# NUC505_v1 register map
File version: 1.0
Registers are 32-bit, read-write, reset 0x0 unless marked. A register's access mark holds for its fields unless they carry their own. Offsets are from the block's base; [hi:lo] are bit positions; 'fields as' and 'values as' point back to an identical list.

## USBD — USBD Register Map
Base 0x40019000
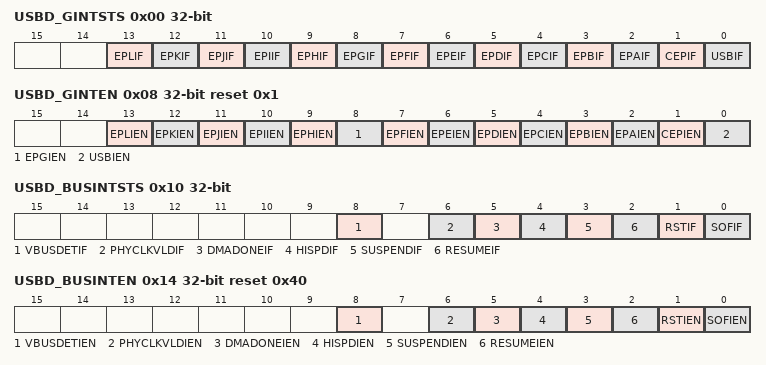
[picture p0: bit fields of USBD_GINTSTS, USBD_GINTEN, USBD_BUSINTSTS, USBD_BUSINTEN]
0x00 USBD_GINTSTS ro — Global Interrupt Status Register
  [all] fields
    0=No interrupt event occurred; 1=The related interrupt event is occurred
  [13] EPLIF — Endpoints L Interrupt. When set, the corresponding Endpoint L's interrupt status register should be read to determine the cause of the interrupt.
  [12] EPKIF — Endpoints K Interrupt. When set, the corresponding Endpoint K's interrupt status register should be read to determine the cause of the interrupt.
  [11] EPJIF — Endpoints J Interrupt. When set, the corresponding Endpoint J's interrupt status register should be read to determine the cause of the interrupt.
  [10] EPIIF — Endpoints I Interrupt. When set, the corresponding Endpoint I's interrupt status register should be read to determine the cause of the interrupt.
  [9] EPHIF — Endpoints H Interrupt. When set, the corresponding Endpoint H's interrupt status register should be read to determine the cause of the interrupt.
  [8] EPGIF — Endpoints G Interrupt. When set, the corresponding Endpoint G's interrupt status register should be read to determine the cause of the interrupt.
  [7] EPFIF — Endpoints F Interrupt. When set, the corresponding Endpoint F's interrupt status register should be read to determine the cause of the interrupt.
  [6] EPEIF — Endpoints E Interrupt. When set, the corresponding Endpoint E's interrupt status register should be read to determine the cause of the interrupt.
  [5] EPDIF — Endpoints D Interrupt. When set, the corresponding Endpoint D's interrupt status register should be read to determine the cause of the interrupt.
  [4] EPCIF — Endpoints C Interrupt. When set, the corresponding Endpoint C's interrupt status register should be read to determine the cause of the interrupt.
  [3] EPBIF — Endpoints B Interrupt. When set, the corresponding Endpoint B's interrupt status register should be read to determine the cause of the interrupt.
  [2] EPAIF — Endpoints a Interrupt. When set, the corresponding Endpoint A's interrupt status register should be read to determine the cause of the interrupt.
  [1] CEPIF — Control Endpoint Interrupt. This bit conveys the interrupt status for control endpoint. When set, Control-ep's interrupt status register should be read to determine the cause of the interrupt.
  [0] USBIF — USB Interrupt. This bit conveys the interrupt status for USB specific events endpoint. When set, USB interrupt status register should be read to determine the cause of the interrupt.
0x08 USBD_GINTEN reset 0x1 — Global Interrupt Enable Register
  [all] fields
    0=The related interrupt Disabled; 1=The related interrupt Enabled
  [13] EPLIEN — Interrupt Enable Control for Endpoint L. When set, this bit enables a local interrupt to be generated when an interrupt is pending for the endpoint L
  [12] EPKIEN — Interrupt Enable Control for Endpoint K. When set, this bit enables a local interrupt to be generated when an interrupt is pending for the endpoint K
  [11] EPJIEN — Interrupt Enable Control for Endpoint J. When set, this bit enables a local interrupt to be generated when an interrupt is pending for the endpoint J
  [10] EPIIEN — Interrupt Enable Control for Endpoint I. When set, this bit enables a local interrupt to be generated when an interrupt is pending for the endpoint I
  [9] EPHIEN — Interrupt Enable Control for Endpoint H. When set, this bit enables a local interrupt to be generated when an interrupt is pending for the endpoint H
  [8] EPGIEN — Interrupt Enable Control for Endpoint G. When set, this bit enables a local interrupt to be generated when an interrupt is pending for the endpoint G
  [7] EPFIEN — Interrupt Enable Control for Endpoint F. When set, this bit enables a local interrupt to be generated when an interrupt is pending for the endpoint F
  [6] EPEIEN — Interrupt Enable Control for Endpoint E. When set, this bit enables a local interrupt to be generated when an interrupt is pending for the endpoint E
  [5] EPDIEN — Interrupt Enable Control for Endpoint D. When set, this bit enables a local interrupt to be generated when an interrupt is pending for the endpoint D
  [4] EPCIEN — Interrupt Enable Control for Endpoint C. When set, this bit enables a local interrupt to be generated when an interrupt is pending for the endpoint C
  [3] EPBIEN — Interrupt Enable Control for Endpoint B. When set, this bit enables a local interrupt to be generated when an interrupt is pending for the endpoint B
  [2] EPAIEN — Interrupt Enable Control for Endpoint a. When set, this bit enables a local interrupt to be generated when an interrupt is pending for the endpoint A.
  [1] CEPIEN — Control Endpoint Interrupt Enable Bit. When set, this bit enables a local interrupt to be generated when an interrupt is pending for the control endpoint.
  [0] USBIEN — USB Interrupt Enable Bit. When set, this bit enables a local interrupt to be generated when a USB event occurs on the bus.
0x10 USBD_BUSINTSTS — USB Bus Interrupt Status Register
  [8] VBUSDETIF — VBUS Detection Interrupt Status. Write 1 to clear this bit to 0.
    0=No VBUS is plug-in; 1=VBUS is plug-in
  [6] PHYCLKVLDIF — Usable Clock Interrupt. Write 1 to clear this bit to 0.
    0=Usable clock is not available; 1=Usable clock is available from the transceiver
  [5] DMADONEIF — DMA Completion Interrupt. Write 1 to clear this bit to 0.
    0=No DMA transfer over; 1=DMA transfer is over
  [4] HISPDIF — High-speed Settle. Write 1 to clear this bit to 0.
    0=No valid high-speed reset protocol is detected; 1=Valid high-speed reset protocol is over and the device has settled in high-speed
  [3] SUSPENDIF — Suspend Request. This bit is set as default and it has to be cleared by writing '1' before the USB reset. This bit is also set when a USB Suspend request is detected from the host. Write 1 to clear this bit to 0.
    0=No USB Suspend request is detected from the host; 1=USB Suspend request is detected from the host
  [2] RESUMEIF — Resume. When set, this bit indicates that a device resume has occurred. Write 1 to clear this bit to 0.
    0=No device resume has occurred; 1=Device resume has occurred
  [1] RSTIF — Reset Status. When set, this bit indicates that either the USB root port reset is end. Write 1 to clear this bit to 0.
    0=No USB root port reset is end; 1=USB root port reset is end
  [0] SOFIF — SOF Receive Control. This bit indicates when a start-of-frame packet has been received. Write 1 to clear this bit to 0.
    0=No start-of-frame packet has been received; 1=Start-of-frame packet has been received
0x14 USBD_BUSINTEN reset 0x40 — USB Bus Interrupt Enable Register
  [8] VBUSDETIEN — VBUS Detection Interrupt Enable Control. This bit enables the VBUS floating detection interrupt.
    0=VBUS floating detection interrupt Disabled; 1=VBUS floating detection interrupt Enabled
  [6] PHYCLKVLDIEN — Usable Clock Interrupt. This bit enables the usable clock interrupt.
    0=Usable clock interrupt Disabled; 1=Usable clock interrupt Enabled
  [5] DMADONEIEN — DMA Completion Interrupt. This bit enables the DMA completion interrupt
    0=DMA completion interrupt Disabled; 1=DMA completion interrupt Enabled
  [4] HISPDIEN — High-speed Settle. This bit enables the high-speed settle interrupt.
    0=High-speed settle interrupt Disabled; 1=High-speed settle interrupt Enabled
  [3] SUSPENDIEN — Suspend Request. This bit enables the Suspend interrupt.
    0=Suspend interrupt Disabled; 1=Suspend interrupt Enabled
  [2] RESUMEIEN — Resume. This bit enables the Resume interrupt.
    0=Resume interrupt Disabled; 1=Resume interrupt Enabled
  [1] RSTIEN — Reset Status. This bit enables the USB-Reset interrupt.
    0=USB-Reset interrupt Disabled; 1=USB-Reset interrupt Enabled
  [0] SOFIEN — SOF Interrupt. This bit enables the SOF interrupt.
    0=SOF interrupt Disabled; 1=SOF interrupt Enabled
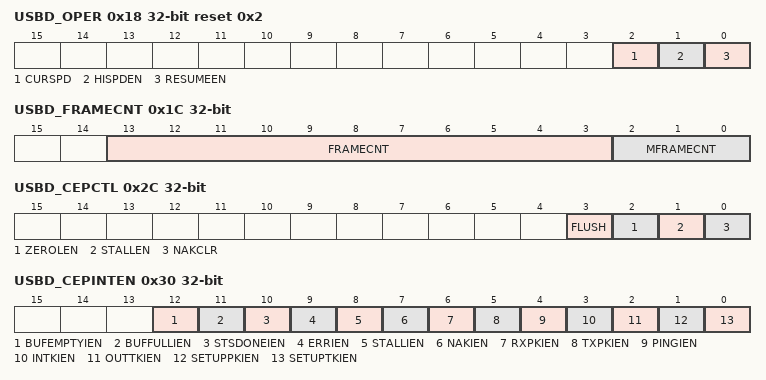
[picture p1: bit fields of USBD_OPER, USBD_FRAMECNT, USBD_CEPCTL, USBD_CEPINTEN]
0x18 USBD_OPER reset 0x2 — USB Operational Register
  [2] CURSPD — Current USB Speed
    0=The device has settled in Full Speed; 1=The USB device controller has settled in High Speed
  [1] HISPDEN — USB High-speed
    0=The USB device controller suppresses the chirp-sequence during reset protocol, thereby allowing the USB device controller to settle in full-speed, even though it is connected to a USB2.0 Host; 1=The USB device controller initiates a chirp-sequence during reset protocol
  [0] RESUMEEN — Generate Resume
    0=No resume sequence to be initiated to the host; 1=A resume sequence to be initiated to the host if device remote wake-up is enabled. Note: This bit is self-cleared
0x1C USBD_FRAMECNT ro — USB Frame Count Register
  [13:3] FRAMECNT — Frame Counter. This field contains the frame count from the most recent start-of-frame packet.
  [2:0] MFRAMECNT — Micro-frame Counter. This field contains the micro-frame number for the frame number in the frame counter field.
0x20 USBD_FADDR — USB Function Address Register
  [6:0] FADDR — USB Function Address. This field contains the current USB address of the device. This field is cleared when a root port reset is detected.
0x24 USBD_TEST — USB Test Mode Register
  [2:0] TESTMODE — Test Mode Selection. Note: This field is cleared when root port reset is detected.
    0=Normal Operation; 1=Test_J; 2=Test_K; 3=Test_SE0_NAK; 4=Test_Packet; 5=Test_Force_Enable
0x28 USBD_CEPDAT — Control-endpoint Data Buffer
  [31:0] DAT — Control-endpoint Data Buffer. Control endpoint data buffer for the buffer transaction (read or write). Only word or byte access is supported.
0x2C USBD_CEPCTL — Control-endpoint Control Register
  [3] FLUSH — CEP-fLUSH Bit
    0=No packet buffer and its corresponding USBD_CEPDATCNT register to be cleared; 1=The packet buffer and its corresponding USBD_CEPDATCNT register to be cleared. This bit is self-cleared
  [2] ZEROLEN — Zero Packet Length. This bit is valid for Auto Validation mode only.
    0=No zero length packet to the host during Data stage to an IN token; 1=USB device controller can send a zero length packet to the host during Data stage to an IN token. This bit gets cleared once the zero length data packet is sent. Thus, the local CPU does not need to write again to clear this bit
  [1] STALLEN — Stall Enable Control. When this stall bit is set, the control endpoint sends a stall handshake in response to any in or out token thereafter. This is typically used for response to invalid/unsupported requests. When this bit is being set the NAK clear bit has to be cleared at the same time since the NAK clear bit has highest priority than STALL. It is automatically cleared on receipt of a next setup-token. Thus, the local CPU does not need to write again to clear this bit. Note: This bit can be updated only when CPU writes data[1:0] 0x2 or 0x0.
    0=No sends a stall handshake in response to any in or out token thereafter; 1=The control endpoint sends a stall handshake in response to any in or out token thereafter
  [0] NAKCLR — No Acknowledge Control. This bit plays a crucial role in any control transfer. Note: This bit can be updated only when CPU writes data[1:0] is 0x2 or 0x0.
    0=The bit is being cleared by the local CPU by writing zero, the USB device controller will be responding with NAKs for the subsequent status phase. This mechanism holds the host from moving to the next request, until the local CPU is also ready to process the next request; 1=This bit is set to one by the USB device controller, whenever a setup token is received. The local CPU can take its own time to finish off any house-keeping work based on the request and then clear this bit
0x30 USBD_CEPINTEN — Control-endpoint Interrupt Enable Control Register
  [12] BUFEMPTYIEN — Buffer Empty Interrupt
    0=The buffer empty interrupt in Control Endpoint Disabled; 1=The buffer empty interrupt in Control Endpoint Enabled
  [11] BUFFULLIEN — Buffer Full Interrupt
    0=The buffer full interrupt in Control Endpoint Disabled; 1=The buffer full interrupt in Control Endpoint Enabled
  [10] STSDONEIEN — Status Completion Interrupt
    0=The Status Completion interrupt in Control Endpoint Disabled; 1=The Status Completion interrupt in Control Endpoint Enabled
  [9] ERRIEN — USB Error Interrupt
    0=The USB Error interrupt in Control Endpoint Disabled; 1=The USB Error interrupt in Control Endpoint Enabled
  [8] STALLIEN — STALL Sent Interrupt
    0=The STALL sent interrupt in Control Endpoint Disabled; 1=The STALL sent interrupt in Control Endpoint Enabled
  [7] NAKIEN — NAK Sent Interrupt
    0=The NAK sent interrupt in Control Endpoint Disabled; 1=The NAK sent interrupt in Control Endpoint Enabled
  [6] RXPKIEN — Data Packet Received Interrupt
    0=The data received interrupt in Control Endpoint Disabled; 1=The data received interrupt in Control Endpoint Enabled
  [5] TXPKIEN — Data Packet Transmitted Interrupt
    0=The data packet transmitted interrupt in Control Endpoint Disabled; 1=The data packet transmitted interrupt in Control Endpoint Enabled
  [4] PINGIEN — Ping Token Interrupt
    0=The ping token interrupt in Control Endpoint Disabled; 1=The ping token interrupt Control Endpoint Enabled
  [3] INTKIEN — in Token Interrupt
    0=The IN token interrupt in Control Endpoint Disabled; 1=The IN token interrupt in Control Endpoint Enabled
  [2] OUTTKIEN — Out Token Interrupt
    0=The OUT token interrupt in Control Endpoint Disabled; 1=The OUT token interrupt in Control Endpoint Enabled
  [1] SETUPPKIEN — Setup Packet Interrupt
    0=The SETUP packet interrupt in Control Endpoint Disabled; 1=The SETUP packet interrupt in Control Endpoint Enabled
  [0] SETUPTKIEN — Setup Token Interrupt Enable Bit
    0=The SETUP token interrupt in Control Endpoint Disabled; 1=The SETUP token interrupt in Control Endpoint Enabled
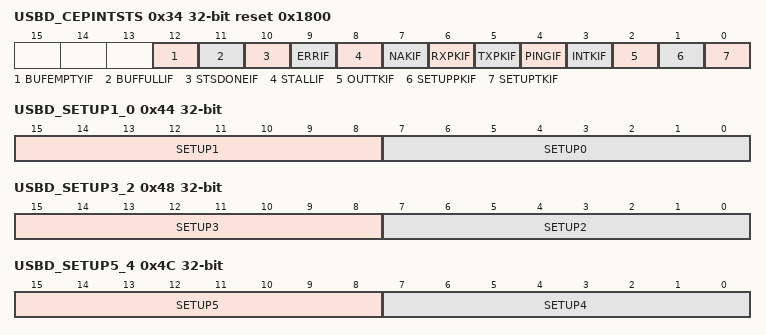
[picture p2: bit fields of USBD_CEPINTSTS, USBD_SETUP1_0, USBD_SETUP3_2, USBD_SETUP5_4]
0x34 USBD_CEPINTSTS reset 0x1800 — Control-endpoint Interrupt Status
  [12] BUFEMPTYIF — Buffer Empty Interrupt. Note: Write 1 to clear this bit to 0.
    0=The control-endpoint buffer is not empty; 1=The control-endpoint buffer is empty
  [11] BUFFULLIF — Buffer Full Interrupt. Note: Write 1 to clear this bit to 0.
    0=The control-endpoint buffer is not full; 1=The control-endpoint buffer is full
  [10] STSDONEIF — Status Completion Interrupt. Note: Write 1 to clear this bit to 0.
    0=No USB transaction has completed successfully; 1=The status stage of a USB transaction has completed successfully
  [9] ERRIF — USB Error Interrupt. Note: Write 1 to clear this bit to 0.
    0=No error had occurred during the transaction; 1=An error had occurred during the transaction
  [8] STALLIF — STALL Sent Interrupt. Note: Write 1 to clear this bit to 0.
    0=No stall-token is sent in response to an IN/OUT token; 1=A stall-token is sent in response to an IN/OUT token
  [7] NAKIF — NAK Sent Interrupt. Note: Write 1 to clear this bit to 0.
    0=No NAK-token is sent in response to an IN/OUT token; 1=A NAK-token is sent in response to an IN/OUT token
  [6] RXPKIF — Data Packet Received Interrupt. Note: Write 1 to clear this bit to 0.
    0=No data packet is successfully received from the host for an OUT-token and an ACK is sent to the host; 1=A data packet is successfully received from the host for an OUT-token and an ACK is sent to the host
  [5] TXPKIF — Data Packet Transmitted Interrupt. Note: Write 1 to clear this bit to 0.
    0=No data packet is successfully transmitted to the host in response to an IN-token and an ACK-token is received for the same; 1=A data packet is successfully transmitted to the host in response to an IN-token and an ACK-token is received for the same
  [4] PINGIF — Ping Token Interrupt. Note: Write 1 to clear this bit to 0.
    0=The control-endpoint does not receive a ping token from the host; 1=The control-endpoint receives a ping token from the host
  [3] INTKIF — in Token Interrupt. Write 1 to clear this bit to 0.
    0=The control-endpoint does not receive an IN token from the host; 1=The control-endpoint receives an IN token from the host
  [2] OUTTKIF — Out Token Interrupt. Note: Write 1 to clear this bit to 0.
    0=The control-endpoint does not receive an OUT token from the host; 1=The control-endpoint receives an OUT token from the host
  [1] SETUPPKIF — Setup Packet Interrupt. This bit must be cleared (by writing 1) before the next setup packet can be received. If the bit is not cleared, then the successive setup packets will be overwritten in the setup packet buffer. Note: Write 1 to clear this bit to 0.
    0=No setup packet has been received from the host; 1=A setup packet has been received from the host
  [0] SETUPTKIF — Setup Token Interrupt. Note: Write 1 to clear this bit to 0.
    0=No setup token is received; 1=A setup token is received. Writing 1 clears this status bit
0x38 USBD_CEPTXCNT — Control-endpoint In-transfer Data Count
  [7:0] TXCNT — In-transfer Data Count. There is no mode selection for the control endpoint (but it operates like manual mode).The local-CPU has to fill the control-endpoint buffer with the data to be sent for an in-token and to write the count of bytes in this register. When zero is written into this field, a zero length packet is sent to the host. When the count written in the register is more than the MPS, the data sent will be of only MPS.
0x3C USBD_CEPRXCNT ro — Control-endpoint Out-transfer Data Count
  [7:0] RXCNT — Out-transfer Data Count. The USB device controller maintains the count of the data received in case of an out transfer, during the control transfer.
0x40 USBD_CEPDATCNT ro — Control-endpoint Data Count
  [15:0] DATCNT — Control-endpoint Data Count. The USB device controller maintains the count of the data of control-endpoint.
0x44 USBD_SETUP1_0 ro — Setup1 Setup0 Bytes
  [15:8] SETUP1 — Setup Byte 1[15:8]. This register provides byte 1 of the last setup packet received. For a Standard Device Request, the following bRequest Code information is returned.
    0=Get Status; 1=Clear Feature; 3=Set Feature; 5=Set Address; 6=Get Descriptor; 7=Set Descriptor; 8=Get Configuration; 9=Set Configuration; 10=Get Interface; 11=Set Interface; 12=Synch Frame
  [7:0] SETUP0 — Setup Byte 0[7:0]. This register provides byte 0 of the last setup packet received. For a Standard Device Request, the following bmRequestType information is returned. Bit 7(Direction):
    0=Host to device. Standard. Device; 1=Device to host. Class. nterface; 10=Vendor. Endpoint; 11=Reserved. :Other
0x48 USBD_SETUP3_2 ro — Setup3 Setup2 Bytes
  [15:8] SETUP3 — Setup Byte 3 [15:8]. This register provides byte 3 of the last setup packet received. For a Standard Device Request, the most significant byte of the wValue field is returned.
  [7:0] SETUP2 — Setup Byte 2 [7:0]. This register provides byte 2 of the last setup packet received. For a Standard Device Request, the least significant byte of the wValue field is returned.
0x4C USBD_SETUP5_4 ro — Setup5 Setup4 Bytes
  [15:8] SETUP5 — Setup Byte 5[15:8]. This register provides byte 5 of the last setup packet received. For a Standard Device Request, the most significant byte of the wIndex field is returned.
  [7:0] SETUP4 — Setup Byte 4[7:0]. This register provides byte 4 of the last setup packet received. For a Standard Device Request, the least significant byte of the wIndex is returned.
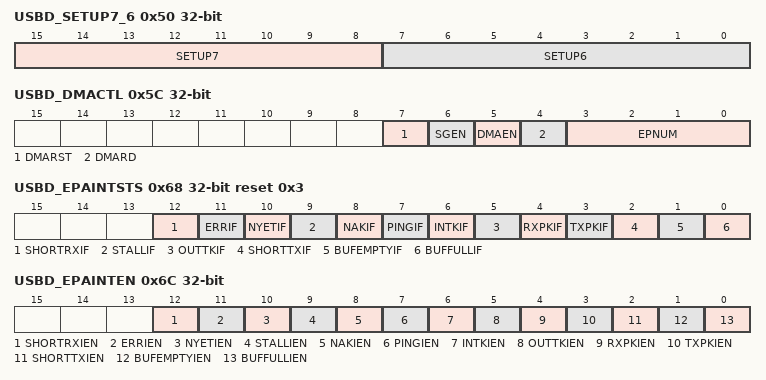
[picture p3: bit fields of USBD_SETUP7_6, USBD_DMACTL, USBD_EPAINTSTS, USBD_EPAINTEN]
0x50 USBD_SETUP7_6 ro — Setup7 Setup6 Bytes
  [15:8] SETUP7 — Setup Byte 7[15:8]. This register provides byte 7 of the last setup packet received. For a Standard Device Request, the most significant byte of the wLength field is returned.
  [7:0] SETUP6 — Setup Byte 6[7:0]. This register provides byte 6 of the last setup packet received. For a Standard Device Request, the least significant byte of the wLength field is returned.
0x54 USBD_CEPBUFSTART — Control Endpoint RAM Start Address Register
  [11:0] SADDR — Control-endpoint Start Address. This is the start-address of the RAM space allocated for the control-endpoint.
0x58 USBD_CEPBUFEND — Control Endpoint RAM End Address Register
  [11:0] EADDR — Control-endpoint End Address. This is the end-address of the RAM space allocated for the control-endpoint.
0x5C USBD_DMACTL — DMA Control Status Register
  [7] DMARST — Reset DMA State Machine
    0=No reset the DMA state machine; 1=Reset the DMA state machine
  [6] SGEN — Scatter Gather Function Enable Bit
    0=Scatter gather function Disabled; 1=Scatter gather function Enabled
  [5] DMAEN — DMA Enable Bit
    0=DMA function Disabled; 1=DMA function Enabled
  [4] DMARD — DMA Operation
    0=The operation is a DMA write (read from USB buffer). DMA will check endpoint data available count (USBD_EPxDATCNT) according to EPNM setting before to perform DMA write operation; 1=The operation is a DMA read (write to USB buffer)
  [3:0] EPNUM — DMA Endpoint Address Bits. Used to define the Endpoint Address
0x60 USBD_DMACNT — DMA Count Register
  [19:0] DMACNT — DMA Transfer Count. The transfer count of the DMA operation to be performed is written to this register.
0x64 USBD_EPADAT — Endpoint A Data Register
  [31:0] EPDAT — Endpoint A~L Data Register. Endpoint A~L data buffer for the buffer transaction (read or write). Only word or byte access are supported.
0x68 USBD_EPAINTSTS reset 0x3 — Endpoint A Interrupt Status Register
  [12] SHORTRXIF — Bulk Out Short Packet Received. Write 1 to clear this bit to 0.
    0=No bulk out short packet is received; 1=Received bulk out short packet (including zero length packet)
  [11] ERRIF — ERR Sent. Write 1 to clear this bit to 0.
    0=No any error in the transaction; 1=There occurs any error in the transaction
  [10] NYETIF — NYET Sent. Write 1 to clear this bit to 0.
    0=The space available in the RAM is sufficient to accommodate the next on coming data packet; 1=The space available in the RAM is not sufficient to accommodate the next on coming data packet
  [9] STALLIF — USB STALL Sent. Write 1 to clear this bit to 0.
    0=The last USB packet could be accepted or provided because the endpoint was stalled, and was acknowledged with a STALL; 1=The last USB packet could not be accepted or provided because the endpoint was stalled, and was acknowledged with a STALL
  [8] NAKIF — USB NAK Sent. Write 1 to clear this bit to 0.
    0=The last USB IN packet could be provided, and was acknowledged with an ACK; 1=The last USB IN packet could not be provided, and was acknowledged with a NAK
  [7] PINGIF — PING Token Interrupt. Write 1 to clear this bit to 0.
    0=A Data PING token has not been received from the host; 1=A Data PING token has been received from the host
  [6] INTKIF — Data IN Token Interrupt. Write 1 to clear this bit to 0.
    0=No Data IN token has been received from the host; 1=A Data IN token has been received from the host
  [5] OUTTKIF — Data OUT Token Interrupt. Note: Write 1 to clear this bit to 0.
    0=A Data OUT token has not been received from the host; 1=A Data OUT token has been received from the host. This bit also set by PING token (in high-speed only)
  [4] RXPKIF — Data Packet Received Interrupt. Note: Write 1 to clear this bit to 0.
    0=No data packet is received from the host by the endpoint; 1=A data packet is received from the host by the endpoint
  [3] TXPKIF — Data Packet Transmitted Interrupt. Note: Write 1 to clear this bit to 0.
    0=No data packet is transmitted from the endpoint to the host; 1=A data packet is transmitted from the endpoint to the host
  [2] SHORTTXIF — Short Packet Transferred Interrupt. Note: Write 1 to clear this bit to 0.
    0=The length of the last packet was not less than the Maximum Packet Size (EPMPS); 1=The length of the last packet was less than the Maximum Packet Size (EPMPS)
  [1] BUFEMPTYIF — Buffer Empty. For an IN endpoint, a buffer is available to the local side for writing up to FIFO full of bytes. Note: This bit is read-only.
    0=The endpoint buffer is not empty. The currently selected buffer does not have a count of 0; 1=The endpoint buffer is empty. The currently selected buffer has a count of 0, or no buffer is available on the local side (nothing to read)
  [0] BUFFULLIF — Buffer Full. For an IN endpoint, the currently selected buffer is full, or no buffer is available to the local side for writing (no space to write). For an OUT endpoint, there is a buffer available on the local side, and there are FIFO full of bytes available to be read (entire packet is available for reading). Note: This bit is read-only.
    0=The endpoint packet buffer is not full; 1=The endpoint packet buffer is full
0x6C USBD_EPAINTEN — Endpoint A Interrupt Enable Register
  [12] SHORTRXIEN — Bulk Out Short Packet Interrupt Enable Bit. When set, this bit enables a local interrupt to be set whenever bulk out short packet occurs on the bus for this endpoint.
    0=Bulk out interrupt Disabled; 1=Bulk out interrupt Enabled
  [11] ERRIEN — ERR Interrupt Enable Bit. When set, this bit enables a local interrupt to be set whenever ERR condition occurs on the bus for this endpoint.
    0=Error event interrupt Disabled; 1=Error event interrupt Enabled
  [10] NYETIEN — NYET Interrupt Enable Bit. When set, this bit enables a local interrupt to be set whenever NYET condition occurs on the bus for this endpoint.
    0=NYET condition interrupt Disabled; 1=NYET condition interrupt Enabled
  [9] STALLIEN — USB STALL Sent Interrupt Enable Bit. When set, this bit enables a local interrupt to be set when a stall token is sent to the host.
    0=STALL token interrupt Disabled; 1=STALL token interrupt Enabled
  [8] NAKIEN — USB NAK Sent Interrupt Enable Bit. When set, this bit enables a local interrupt to be set when a NAK token is sent to the host.
    0=NAK token interrupt Disabled; 1=NAK token interrupt Enabled
  [7] PINGIEN — PING Token Interrupt Enable Bit. When set, this bit enables a local interrupt to be set when a PING token has been received from the host.
    0=PING token interrupt Disabled; 1=PING token interrupt Enabled
  [6] INTKIEN — Data IN Token Interrupt Enable Bit. When set, this bit enables a local interrupt to be set when a Data IN token has been received from the host.
    0=Data IN token interrupt Disabled; 1=Data IN token interrupt Enabled
  [5] OUTTKIEN — Data OUT Token Interrupt Enable Bit. When set, this bit enables a local interrupt to be set when a Data OUT token has been received from the host.
    0=Data OUT token interrupt Disabled; 1=Data OUT token interrupt Enabled
  [4] RXPKIEN — Data Packet Received Interrupt Enable Bit. When set, this bit enables a local interrupt to be set when a data packet has been transmitted to the host.
    0=Data packet has been transmitted to the host interrupt Disabled; 1=Data packet has been transmitted to the host interrupt Enabled
  [3] TXPKIEN — Data Packet Transmitted Interrupt Enable Bit. When set, this bit enables a local interrupt to be set when a data packet has been received from the host.
    0=Data packet has been received from the host interrupt Disabled; 1=Data packet has been received from the host interrupt Enabled
  [2] SHORTTXIEN — Short Packet Transferred Interrupt Enable Bit. When set, this bit enables a local interrupt to be set when a short data packet has been transferred to/from the host.
    0=Short data packet interrupt Disabled; 1=Short data packet interrupt Enabled
  [1] BUFEMPTYIEN — Buffer Empty Interrupt. When set, this bit enables a local interrupt to be set when a buffer empty condition is detected on the bus.
    0=Buffer empty interrupt Disabled; 1=Buffer empty interrupt Enabled
  [0] BUFFULLIEN — Buffer Full Interrupt. When set, this bit enables a local interrupt to be set when a buffer full condition is detected on the bus.
    0=Buffer full interrupt Disabled; 1=Buffer full interrupt Enabled
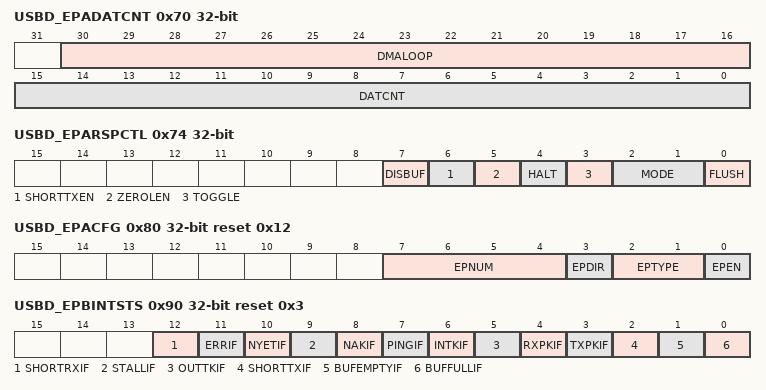
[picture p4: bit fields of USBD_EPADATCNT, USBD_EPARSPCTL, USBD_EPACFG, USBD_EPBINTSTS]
0x70 USBD_EPADATCNT ro — Endpoint A Data Available Count Register
  [30:16] DMALOOP — DMA Loop. This register is the remaining DMA loop to complete. Each loop means 32-byte transfer.
  [15:0] DATCNT — Data Count. For an IN endpoint (EPDIR(USBD_EPxCFG[3] is high.), this register returns the number of valid bytes in the IN endpoint packet buffer. For an OUT endpoint (EPDIR(USBD_EPxCFG[3] is low.), this register returns the number of received valid bytes in the Host OUT transfer.
0x74 USBD_EPARSPCTL — Endpoint A Response Control Register
  [7] DISBUF — Buffer Disable Bit. This bit is used to receive unknown size OUT short packet. The received packet size is reference USBD_EPxDATCNT register.
    0=Buffer Not Disabled when Bulk-OUT short packet is received; 1=Buffer Disabled when Bulk-OUT short packet is received
  [6] SHORTTXEN — Short Packet Transfer Enable Bit. This bit is applicable only in case of Auto-Validate Method. This bit is set to validate any remaining data in the buffer which is not equal to the MPS of the endpoint, and happens to be the last transfer. This bit gets cleared once the data packet is sent.
    0=Not validate any remaining data in the buffer which is not equal to the MPS of the endpoint; 1=Validate any remaining data in the buffer which is not equal to the MPS of the endpoint
  [5] ZEROLEN — Zero Length. This bit is used to send a zero-length packet response to an IN-token. When this bit is set, a zero packet is sent to the host on reception of an IN-token. This bit gets cleared once the zero length data packet is sent.
    0=A zero packet is not sent to the host on reception of an IN-token; 1=A zero packet is sent to the host on reception of an IN-token
  [4] HALT — Endpoint Halt. This bit is used to send a STALL handshake as response to the token from the host. When an Endpoint Set Feature (ep_halt) is detected by the local CPU, it must write a '1' to this bit.
    0=Do not send a STALL handshake as response to the token from the host; 1=Send a STALL handshake as response to the token from the host
  [3] TOGGLE — Endpoint Toggle. This bit is used to clear the endpoint data toggle bit. Reading this bit returns the current state of the endpoint data toggle bit. The local CPU may use this bit to initialize the end-point's toggle in case of reception of a Set Interface request or a Clear Feature (ep_halt) request from the host. Only when toggle bit is "1", this bit can be written into the inversed write data bit[3].
    0=Do not clear the endpoint data toggle bit; 1=Clear the endpoint data toggle bit
  [2:1] MODE — Mode Control. The two bits determine the operation mode of the in-endpoint. Note: These bits are not valid for an out-endpoint. The auto validate mode will be activated when the reserved mode is selected.
    0=Auto-Validate Mode; 1=Manual-Validate Mode; 2=Fly Mode
  [0] FLUSH — Buffer Flush. Writing 1 to this bit causes the packet buffer to be flushed and the corresponding EP_AVAIL register to be cleared. This bit is self-cleared. This bit should always be written after a configuration event.
    0=The packet buffer is not flushed; 1=The packet buffer is flushed by user
0x78 USBD_EPAMPS — Endpoint A Maximum Packet Size Register
  [10:0] EPMPS — Endpoint Maximum Packet Size. This field determines the Maximum Packet Size of the Endpoint.
0x7C USBD_EPATXCNT — Endpoint A Transfer Count Register
  [10:0] TXCNT — Endpoint Transfer Count. For IN endpoints, this field determines the total number of bytes to be sent to the host in case of manual validation method. For OUT endpoints, this field has no effect.
0x80 USBD_EPACFG reset 0x12 — Endpoint A Configuration Register
  [7:4] EPNUM — Endpoint Number. This field selects the number of the endpoint. Valid numbers 1 to 15. Do not support two endpoints have same endpoint number.
  [3] EPDIR — Endpoint Direction. A maximum of one OUT and IN endpoint is allowed for each endpoint number.
    0=out-endpoint (Host OUT to Device); 1=in-endpoint (Host IN to Device)
  [2:1] EPTYPE — Endpoint Type. This field selects the type of this endpoint. Endpoint 0 is forced to a Control type.
    1=Bulk; 2=Interrupt; 3=Isochronous
  [0] EPEN — Endpoint Valid. When set, this bit enables this endpoint. This bit has no effect on Endpoint 0, which is always enabled.
    0=The endpoint Disabled; 1=The endpoint Enabled
0x84 USBD_EPABUFSTART — Endpoint A RAM Start Address Register
  [11:0] SADDR — Endpoint Start Address. This is the start-address of the RAM space allocated for the endpoint A~L.
0x88 USBD_EPABUFEND — Endpoint A RAM End Address Register
  [11:0] EADDR — Endpoint End Address. This is the end-address of the RAM space allocated for the endpoint A~L.
0x8C USBD_EPBDAT — Endpoint B Data Register
  fields as USBD_EPADAT
0x90 USBD_EPBINTSTS reset 0x3 — Endpoint B Interrupt Status Register
  fields as USBD_EPAINTSTS
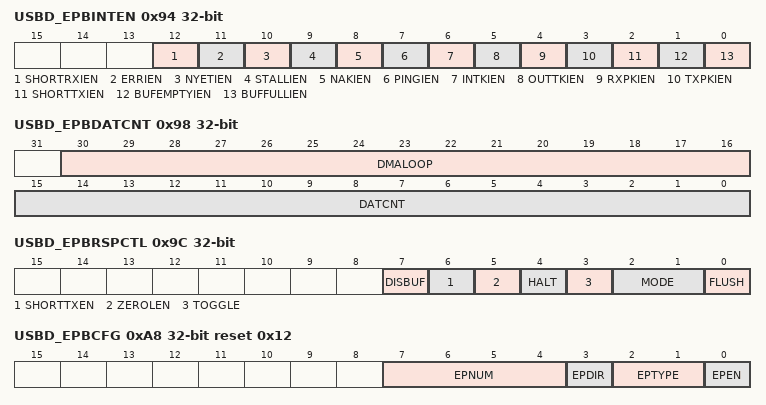
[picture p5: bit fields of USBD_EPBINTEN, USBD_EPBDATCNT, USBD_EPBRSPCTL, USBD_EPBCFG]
0x94 USBD_EPBINTEN — Endpoint B Interrupt Enable Register
  fields as USBD_EPAINTEN
0x98 USBD_EPBDATCNT ro — Endpoint B Data Available Count Register
  fields as USBD_EPADATCNT
0x9C USBD_EPBRSPCTL — Endpoint B Response Control Register
  fields as USBD_EPARSPCTL
0xA0 USBD_EPBMPS — Endpoint B Maximum Packet Size Register
  fields as USBD_EPAMPS
0xA4 USBD_EPBTXCNT — Endpoint B Transfer Count Register
  fields as USBD_EPATXCNT
0xA8 USBD_EPBCFG reset 0x12 — Endpoint B Configuration Register
  fields as USBD_EPACFG
0xAC USBD_EPBBUFSTART — Endpoint B RAM Start Address Register
  fields as USBD_EPABUFSTART
0xB0 USBD_EPBBUFEND — Endpoint B RAM End Address Register
  fields as USBD_EPABUFEND
0xB4 USBD_EPCDAT — Endpoint C Data Register
  fields as USBD_EPADAT
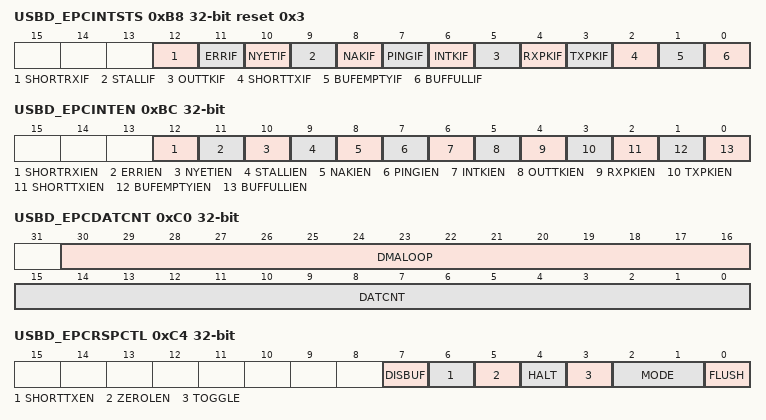
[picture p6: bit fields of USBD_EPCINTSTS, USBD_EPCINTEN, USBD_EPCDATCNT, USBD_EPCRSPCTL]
0xB8 USBD_EPCINTSTS reset 0x3 — Endpoint C Interrupt Status Register
  fields as USBD_EPAINTSTS
0xBC USBD_EPCINTEN — Endpoint C Interrupt Enable Register
  fields as USBD_EPAINTEN
0xC0 USBD_EPCDATCNT ro — Endpoint C Data Available Count Register
  fields as USBD_EPADATCNT
0xC4 USBD_EPCRSPCTL — Endpoint C Response Control Register
  fields as USBD_EPARSPCTL
0xC8 USBD_EPCMPS — Endpoint C Maximum Packet Size Register
  fields as USBD_EPAMPS
0xCC USBD_EPCTXCNT — Endpoint C Transfer Count Register
  fields as USBD_EPATXCNT
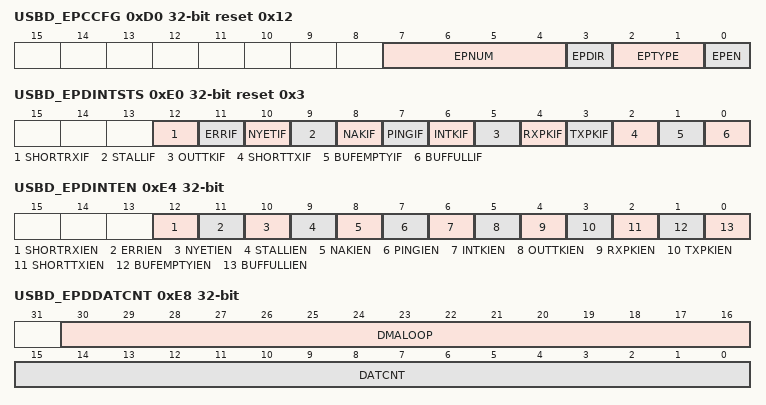
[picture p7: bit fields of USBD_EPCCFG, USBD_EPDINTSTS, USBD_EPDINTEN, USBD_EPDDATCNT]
0xD0 USBD_EPCCFG reset 0x12 — Endpoint C Configuration Register
  fields as USBD_EPACFG
0xD4 USBD_EPCBUFSTART — Endpoint C RAM Start Address Register
  fields as USBD_EPABUFSTART
0xD8 USBD_EPCBUFEND — Endpoint C RAM End Address Register
  fields as USBD_EPABUFEND
0xDC USBD_EPDDAT — Endpoint D Data Register
  fields as USBD_EPADAT
0xE0 USBD_EPDINTSTS reset 0x3 — Endpoint D Interrupt Status Register
  fields as USBD_EPAINTSTS
0xE4 USBD_EPDINTEN — Endpoint D Interrupt Enable Register
  fields as USBD_EPAINTEN
0xE8 USBD_EPDDATCNT ro — Endpoint D Data Available Count Register
  fields as USBD_EPADATCNT
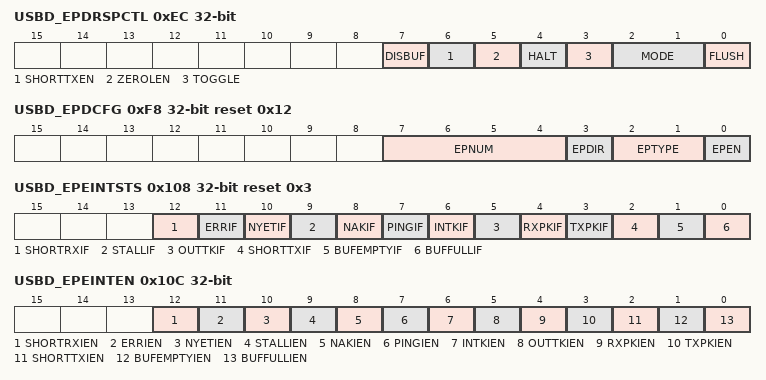
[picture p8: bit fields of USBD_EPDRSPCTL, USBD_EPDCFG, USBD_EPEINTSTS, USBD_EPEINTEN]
0xEC USBD_EPDRSPCTL — Endpoint D Response Control Register
  fields as USBD_EPARSPCTL
0xF0 USBD_EPDMPS — Endpoint D Maximum Packet Size Register
  fields as USBD_EPAMPS
0xF4 USBD_EPDTXCNT — Endpoint D Transfer Count Register
  fields as USBD_EPATXCNT
0xF8 USBD_EPDCFG reset 0x12 — Endpoint D Configuration Register
  fields as USBD_EPACFG
0xFC USBD_EPDBUFSTART — Endpoint D RAM Start Address Register
  fields as USBD_EPABUFSTART
0x100 USBD_EPDBUFEND — Endpoint D RAM End Address Register
  fields as USBD_EPABUFEND
0x104 USBD_EPEDAT — Endpoint E Data Register
  fields as USBD_EPADAT
0x108 USBD_EPEINTSTS reset 0x3 — Endpoint E Interrupt Status Register
  fields as USBD_EPAINTSTS
0x10C USBD_EPEINTEN — Endpoint E Interrupt Enable Register
  fields as USBD_EPAINTEN
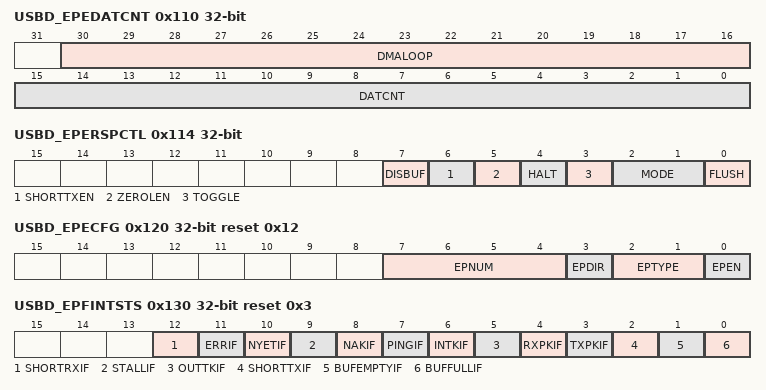
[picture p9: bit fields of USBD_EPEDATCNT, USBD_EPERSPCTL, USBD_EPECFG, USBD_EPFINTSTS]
0x110 USBD_EPEDATCNT ro — Endpoint E Data Available Count Register
  fields as USBD_EPADATCNT
0x114 USBD_EPERSPCTL — Endpoint E Response Control Register
  fields as USBD_EPARSPCTL
0x118 USBD_EPEMPS — Endpoint E Maximum Packet Size Register
  fields as USBD_EPAMPS
0x11C USBD_EPETXCNT — Endpoint E Transfer Count Register
  fields as USBD_EPATXCNT
0x120 USBD_EPECFG reset 0x12 — Endpoint E Configuration Register
  fields as USBD_EPACFG
0x124 USBD_EPEBUFSTART — Endpoint E RAM Start Address Register
  fields as USBD_EPABUFSTART
0x128 USBD_EPEBUFEND — Endpoint E RAM End Address Register
  fields as USBD_EPABUFEND
0x12C USBD_EPFDAT — Endpoint F Data Register
  fields as USBD_EPADAT
0x130 USBD_EPFINTSTS reset 0x3 — Endpoint F Interrupt Status Register
  fields as USBD_EPAINTSTS
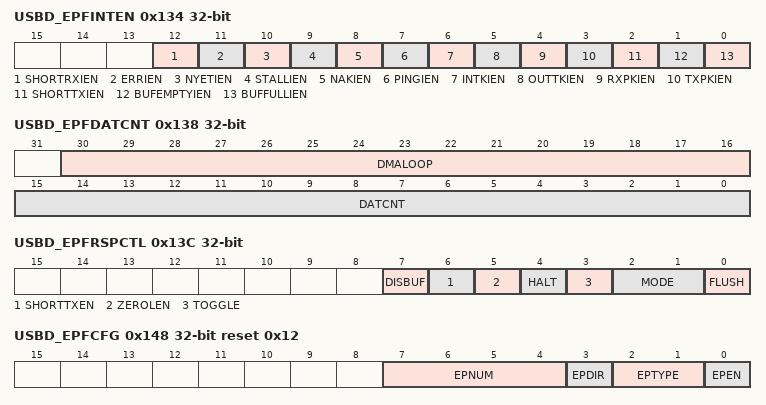
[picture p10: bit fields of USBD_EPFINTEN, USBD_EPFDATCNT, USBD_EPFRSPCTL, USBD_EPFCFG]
0x134 USBD_EPFINTEN — Endpoint F Interrupt Enable Register
  fields as USBD_EPAINTEN
0x138 USBD_EPFDATCNT ro — Endpoint F Data Available Count Register
  fields as USBD_EPADATCNT
0x13C USBD_EPFRSPCTL — Endpoint F Response Control Register
  fields as USBD_EPARSPCTL
0x140 USBD_EPFMPS — Endpoint F Maximum Packet Size Register
  fields as USBD_EPAMPS
0x144 USBD_EPFTXCNT — Endpoint F Transfer Count Register
  fields as USBD_EPATXCNT
0x148 USBD_EPFCFG reset 0x12 — Endpoint F Configuration Register
  fields as USBD_EPACFG
0x14C USBD_EPFBUFSTART — Endpoint F RAM Start Address Register
  fields as USBD_EPABUFSTART
0x150 USBD_EPFBUFEND — Endpoint F RAM End Address Register
  fields as USBD_EPABUFEND
0x154 USBD_EPGDAT — Endpoint G Data Register
  fields as USBD_EPADAT
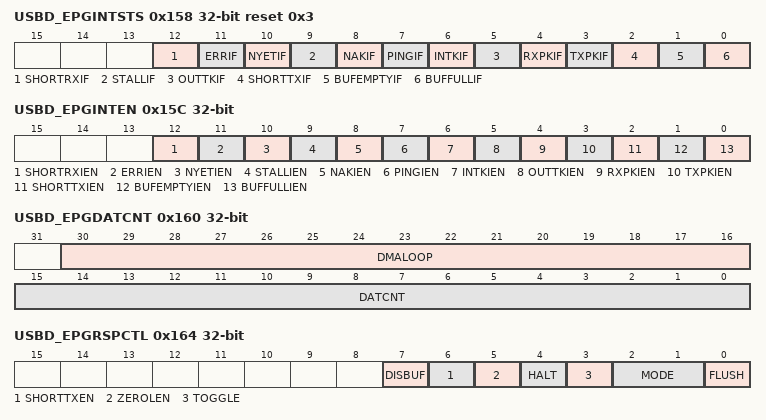
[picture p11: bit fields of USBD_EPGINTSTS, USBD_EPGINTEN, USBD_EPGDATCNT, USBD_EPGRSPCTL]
0x158 USBD_EPGINTSTS reset 0x3 — Endpoint G Interrupt Status Register
  fields as USBD_EPAINTSTS
0x15C USBD_EPGINTEN — Endpoint G Interrupt Enable Register
  fields as USBD_EPAINTEN
0x160 USBD_EPGDATCNT ro — Endpoint G Data Available Count Register
  fields as USBD_EPADATCNT
0x164 USBD_EPGRSPCTL — Endpoint G Response Control Register
  fields as USBD_EPARSPCTL
0x168 USBD_EPGMPS — Endpoint G Maximum Packet Size Register
  fields as USBD_EPAMPS
0x16C USBD_EPGTXCNT — Endpoint G Transfer Count Register
  fields as USBD_EPATXCNT
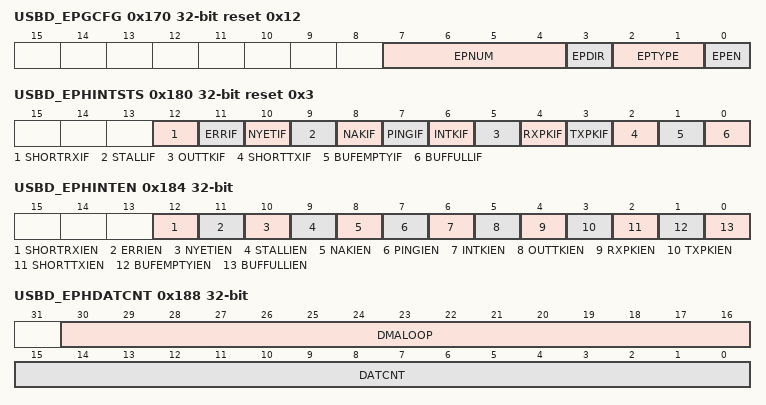
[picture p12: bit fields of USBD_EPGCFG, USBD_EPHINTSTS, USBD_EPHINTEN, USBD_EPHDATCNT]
0x170 USBD_EPGCFG reset 0x12 — Endpoint G Configuration Register
  fields as USBD_EPACFG
0x174 USBD_EPGBUFSTART — Endpoint G RAM Start Address Register
  fields as USBD_EPABUFSTART
0x178 USBD_EPGBUFEND — Endpoint G RAM End Address Register
  fields as USBD_EPABUFEND
0x17C USBD_EPHDAT — Endpoint H Data Register
  fields as USBD_EPADAT
0x180 USBD_EPHINTSTS reset 0x3 — Endpoint H Interrupt Status Register
  fields as USBD_EPAINTSTS
0x184 USBD_EPHINTEN — Endpoint H Interrupt Enable Register
  fields as USBD_EPAINTEN
0x188 USBD_EPHDATCNT ro — Endpoint H Data Available Count Register
  fields as USBD_EPADATCNT
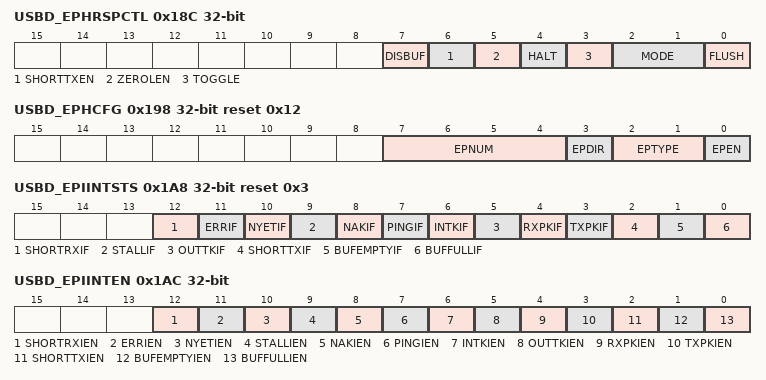
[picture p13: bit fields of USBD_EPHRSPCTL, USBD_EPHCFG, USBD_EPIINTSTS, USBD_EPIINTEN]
0x18C USBD_EPHRSPCTL — Endpoint H Response Control Register
  fields as USBD_EPARSPCTL
0x190 USBD_EPHMPS — Endpoint H Maximum Packet Size Register
  fields as USBD_EPAMPS
0x194 USBD_EPHTXCNT — Endpoint H Transfer Count Register
  fields as USBD_EPATXCNT
0x198 USBD_EPHCFG reset 0x12 — Endpoint H Configuration Register
  fields as USBD_EPACFG
0x19C USBD_EPHBUFSTART — Endpoint H RAM Start Address Register
  fields as USBD_EPABUFSTART
0x1A0 USBD_EPHBUFEND — Endpoint H RAM End Address Register
  fields as USBD_EPABUFEND
0x1A4 USBD_EPIDAT — Endpoint I Data Register
  fields as USBD_EPADAT
0x1A8 USBD_EPIINTSTS reset 0x3 — Endpoint I Interrupt Status Register
  fields as USBD_EPAINTSTS
0x1AC USBD_EPIINTEN — Endpoint I Interrupt Enable Register
  fields as USBD_EPAINTEN
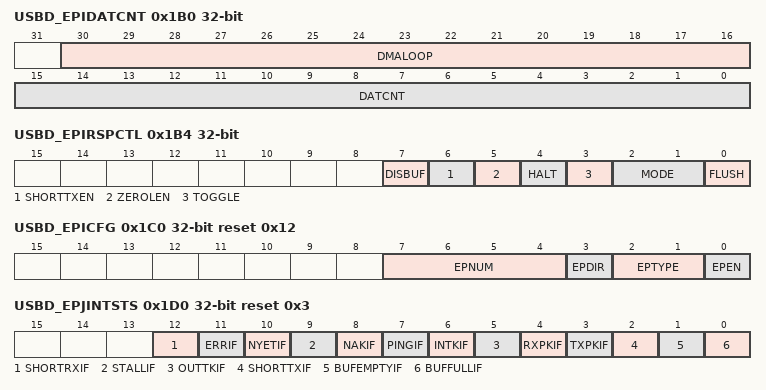
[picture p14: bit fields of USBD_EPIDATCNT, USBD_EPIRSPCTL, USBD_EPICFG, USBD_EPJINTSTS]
0x1B0 USBD_EPIDATCNT ro — Endpoint I Data Available Count Register
  fields as USBD_EPADATCNT
0x1B4 USBD_EPIRSPCTL — Endpoint I Response Control Register
  fields as USBD_EPARSPCTL
0x1B8 USBD_EPIMPS — Endpoint I Maximum Packet Size Register
  fields as USBD_EPAMPS
0x1BC USBD_EPITXCNT — Endpoint I Transfer Count Register
  fields as USBD_EPATXCNT
0x1C0 USBD_EPICFG reset 0x12 — Endpoint I Configuration Register
  fields as USBD_EPACFG
0x1C4 USBD_EPIBUFSTART — Endpoint I RAM Start Address Register
  fields as USBD_EPABUFSTART
0x1C8 USBD_EPIBUFEND — Endpoint I RAM End Address Register
  fields as USBD_EPABUFEND
0x1CC USBD_EPJDAT — Endpoint J Data Register
  fields as USBD_EPADAT
0x1D0 USBD_EPJINTSTS reset 0x3 — Endpoint J Interrupt Status Register
  fields as USBD_EPAINTSTS
0x1D4 USBD_EPJINTEN — Endpoint J Interrupt Enable Register
  fields as USBD_EPAINTEN
0x1D8 USBD_EPJDATCNT ro — Endpoint J Data Available Count Register
  fields as USBD_EPADATCNT
0x1DC USBD_EPJRSPCTL — Endpoint J Response Control Register
  fields as USBD_EPARSPCTL
0x1E0 USBD_EPJMPS — Endpoint J Maximum Packet Size Register
  fields as USBD_EPAMPS
0x1E4 USBD_EPJTXCNT — Endpoint J Transfer Count Register
  fields as USBD_EPATXCNT
0x1E8 USBD_EPJCFG reset 0x12 — Endpoint J Configuration Register
  fields as USBD_EPACFG
0x1EC USBD_EPJBUFSTART — Endpoint J RAM Start Address Register
  fields as USBD_EPABUFSTART
0x1F0 USBD_EPJBUFEND — Endpoint J RAM End Address Register
  fields as USBD_EPABUFEND
0x1F4 USBD_EPKDAT — Endpoint K Data Register
  fields as USBD_EPADAT
0x1F8 USBD_EPKINTSTS reset 0x3 — Endpoint K Interrupt Status Register
  fields as USBD_EPAINTSTS
0x1FC USBD_EPKINTEN — Endpoint K Interrupt Enable Register
  fields as USBD_EPAINTEN
0x200 USBD_EPKDATCNT ro — Endpoint K Data Available Count Register
  fields as USBD_EPADATCNT
0x204 USBD_EPKRSPCTL — Endpoint K Response Control Register
  fields as USBD_EPARSPCTL
0x208 USBD_EPKMPS — Endpoint K Maximum Packet Size Register
  fields as USBD_EPAMPS
0x20C USBD_EPKTXCNT — Endpoint K Transfer Count Register
  fields as USBD_EPATXCNT
0x210 USBD_EPKCFG reset 0x12 — Endpoint K Configuration Register
  fields as USBD_EPACFG
0x214 USBD_EPKBUFSTART — Endpoint K RAM Start Address Register
  fields as USBD_EPABUFSTART
0x218 USBD_EPKBUFEND — Endpoint K RAM End Address Register
  fields as USBD_EPABUFEND
0x21C USBD_EPLDAT — Endpoint L Data Register
  fields as USBD_EPADAT
0x220 USBD_EPLINTSTS reset 0x3 — Endpoint L Interrupt Status Register
  fields as USBD_EPAINTSTS
0x224 USBD_EPLINTEN — Endpoint L Interrupt Enable Register
  fields as USBD_EPAINTEN
0x228 USBD_EPLDATCNT ro — Endpoint L Data Available Count Register
  fields as USBD_EPADATCNT
0x22C USBD_EPLRSPCTL — Endpoint L Response Control Register
  fields as USBD_EPARSPCTL
0x230 USBD_EPLMPS — Endpoint L Maximum Packet Size Register
  fields as USBD_EPAMPS
0x234 USBD_EPLTXCNT — Endpoint L Transfer Count Register
  fields as USBD_EPATXCNT
0x238 USBD_EPLCFG reset 0x12 — Endpoint L Configuration Register
  fields as USBD_EPACFG
0x23C USBD_EPLBUFSTART — Endpoint L RAM Start Address Register
  fields as USBD_EPABUFSTART
0x240 USBD_EPLBUFEND — Endpoint L RAM End Address Register
  fields as USBD_EPABUFEND
0x248 USBD_UVCHDAT0 — USB Header Word0
  [31:0] DAT — The first head data(byte 0 was sent first)
0x24C USBD_UVCHDAT1 — USB Header Word1
  [31:0] DAT — The second head data(byte 0 was sent first)
0x250 USBD_UVCHDAT2 — USB Header Word2
  [31:0] DAT — The third head data(byte 0 was sent first)
0x254 USBD_UVCEPAHCNT — Endpoint A Header Count
  [3:0] CNT — This is the header count for the endpoint A~L The header count must be EVEN.
0x258 USBD_UVCEPBHCNT — Endpoint B Header Count
  fields as USBD_UVCEPAHCNT
0x25C USBD_UVCEPCHCNT — Endpoint C Header Count
  fields as USBD_UVCEPAHCNT
0x260 USBD_UVCEPDHCNT — Endpoint D Header Count
  fields as USBD_UVCEPAHCNT
0x264 USBD_UVCEPEHCNT — Endpoint E Header Count
  fields as USBD_UVCEPAHCNT
0x268 USBD_UVCEPFHCNT — Endpoint F Header Count
  fields as USBD_UVCEPAHCNT
0x26C USBD_UVCEPGHCNT — Endpoint G Header Count
  fields as USBD_UVCEPAHCNT
0x270 USBD_UVCEPHHCNT — Endpoint H Header Count
  fields as USBD_UVCEPAHCNT
0x274 USBD_UVCEPIHCNT — Endpoint I Header Count
  fields as USBD_UVCEPAHCNT
0x278 USBD_UVCEPJHCNT — Endpoint J Header Count
  fields as USBD_UVCEPAHCNT
0x27C USBD_UVCEPKHCNT — Endpoint K Header Count
  fields as USBD_UVCEPAHCNT
0x280 USBD_UVCEPLHCNT — Endpoint L Header Count
  fields as USBD_UVCEPAHCNT
0x700 USBD_DMAADDR — AHB DMA Address Register
  [31:0] DMAADDR — DMAADDR. The register specifies the address from which the DMA has to read / write. The address must WORD (32-bit) aligned.
0x704 USBD_PHYCTL reset 0x420 — USB PHY Control Register
  [31] VBUSDET — VBUS Status
    0=The VBUS is not detected yet; 1=The VBUS is detected
  [24] WKEN — Wake-up Enable Bit
    0=The wake-up function Disabled; 1=The wake-up function Enabled
  [9] PHYEN — PHY Suspend Enable Bit
    0=The USB PHY is suspend; 1=The USB PHY is not suspend
  [8] DPPUEN — DP Pull-up
    0=Pull-up resistor on D+ Disabled; 1=Pull-up resistor on D+ Enabled
  [3] LOWPWREN — PHY Low Power Mode Enable Bit (Low Active). USB PHY HS low power mode configuration control bit. When this bit is 0, USB PHY is in Low Power Mode and USB PHY TX driver is enable only when USB Device Controller (USBD) transmit the data out to USB bus. In this mode, HS signal quality is not guaranteed.
    0=USB PHY Low Power Mode Enabled; 1=USB PHY Low Power Mode Disabled
